# FM33FH0XX register map
File version: 1.0
CPU: SC000 r1p0, little endian, no MPU, no FPU, 3 interrupt priority bits
Registers are 32-bit, read-write, reset 0x0 unless marked. A register's access mark holds for its fields unless they carry their own. Offsets are from the block's base; [hi:lo] are bit positions; {n}, {i} and the like mark numbered series.

## RTC — RTC module information
Base 0x40011000
0x00 WER
  [0] WE — WE field description
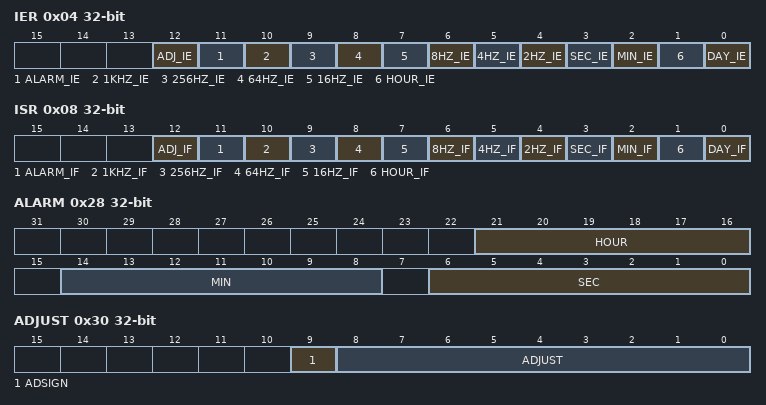
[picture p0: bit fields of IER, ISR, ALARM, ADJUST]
0x04 IER
  [12] ADJ_IE — ADJ_IE field description
  [11] ALARM_IE — ALARM_IE field description
  [10] 1KHZ_IE — 1KHZ_IE field description
  [9] 256HZ_IE — 256HZ_IE field description
  [8] 64HZ_IE — 64HZ_IE field description
  [7] 16HZ_IE — 16HZ_IE field description
  [6] 8HZ_IE — 8HZ_IE field description
  [5] 4HZ_IE — 4HZ_IE field description
  [4] 2HZ_IE — 2HZ_IE field description
  [3] SEC_IE — SEC_IE field description
  [2] MIN_IE — MIN_IE field description
  [1] HOUR_IE — HOUR_IE field description
  [0] DAY_IE — DAY_IE field description
0x08 ISR
  [12] ADJ_IF — ADJ_IF field description
  [11] ALARM_IF — ALARM_IF field description
  [10] 1KHZ_IF — 1KHZ_IF field description
  [9] 256HZ_IF — 256HZ_IF field description
  [8] 64HZ_IF — 64HZ_IF field description
  [7] 16HZ_IF — 16HZ_IF field description
  [6] 8HZ_IF — 8HZ_IF field description
  [5] 4HZ_IF — 4HZ_IF field description
  [4] 2HZ_IF — 2HZ_IF field description
  [3] SEC_IF — SEC_IF field description
  [2] MIN_IF — MIN_IF field description
  [1] HOUR_IF — HOUR_IF field description
  [0] DAY_IF — DAY_IF field description
0x0C BCDSEC
  [6:0] SEC — SEC field description
0x10 BCDMIN
  [6:0] MIN — MIN field description
0x14 BCDHOUR
  [5:0] HOUR — HOUR field description
0x18 BCDDAY
  [5:0] DAY — DAY field description
0x1C BCDWEEK
  [2:0] WEEK — WEEK field description
0x20 BCDMONTH
  [4:0] MONTH — MONTH field description
0x24 BCDYEAR
  [7:0] YEAR — YEAR field description
0x28 ALARM
  [21:16] HOUR — HOUR field description
  [14:8] MIN — MIN field description
  [6:0] SEC — SEC field description
0x2C TMSEL
  [3:0] TMSEL — TMSEL field description
0x30 ADJUST
  [9] ADSIGN — ADSIGN field description
  [8:0] ADJUST — ADJUST field description
0x3C MSECCNT
  [7:0] MSCNT — MSCNT field description
0x40 RTCA_CR
  [0] RTCA_EN — RTCA_EN field description

## SCU — SCU module information
Base 0x40000000
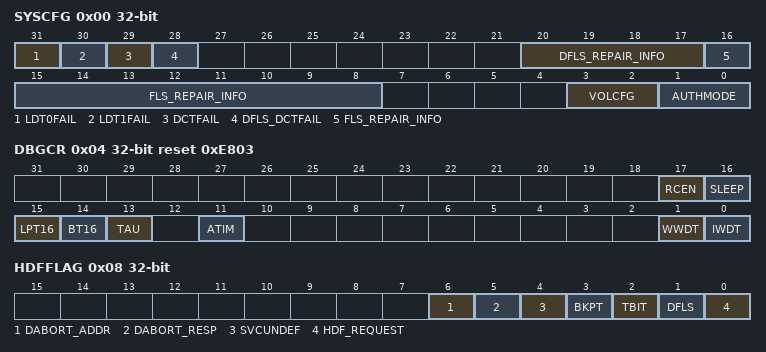
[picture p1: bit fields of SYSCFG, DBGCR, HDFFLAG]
0x00 SYSCFG
  [31] LDT0FAIL ro — LDT0FAIL field description
  [30] LDT1FAIL ro — LDT1FAIL field description
  [29] DCTFAIL ro — DCTFAIL field description
  [28] DFLS_DCTFAIL ro — DFLS_DCTFAIL field description
  [20:17] DFLS_REPAIR_INFO ro — DFLS_REPAIR_INFO field description
  [16:8] FLS_REPAIR_INFO ro — FLS_REPAIR_INFO field description
  [3:2] VOLCFG ro — VOLCFG field description
  [1:0] AUTHMODE ro — AUTHMODE field description
0x04 DBGCR reset 0xE803
  [17] RCEN — RCEN field description
  [16] SLEEP — SLEEP field description
  [15] LPT16 — LPT16 field description
  [14] BT16 — BT16 field description
  [13] TAU — TAU field description
  [11] ATIM — ATIM field description
  [1] WWDT — WWDT field description
  [0] IWDT — IWDT field description
0x08 HDFFLAG
  [6] DABORT_ADDR — DABORT_ADDR field description
  [5] DABORT_RESP — DABORT_RESP field description
  [4] SVCUNDEF — SVCUNDEF field description
  [3] BKPT — BKPT field description
  [2] TBIT — TBIT field description
  [1] DFLS — DFLS field description
  [0] HDF_REQUEST — HDF_REQUEST field description

## SENT0 — SENT0 module information
Base 0x40014800
Same registers: SENT1 0x40014C00
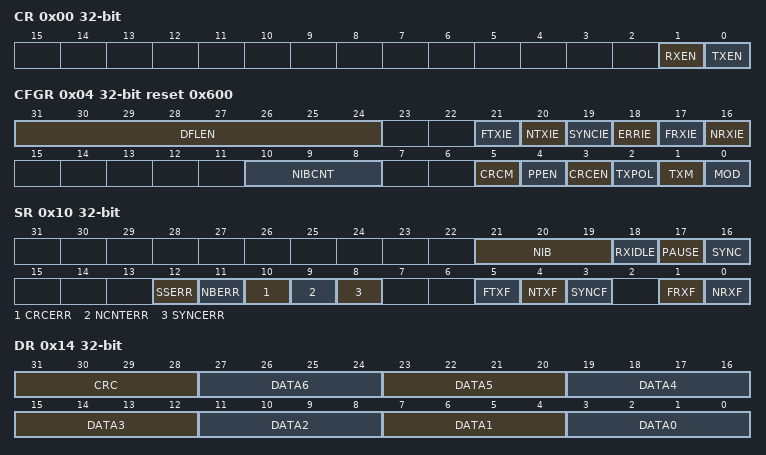
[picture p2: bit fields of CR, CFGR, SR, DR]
0x00 CR
  [1] RXEN — RXEN field description
  [0] TXEN — TXEN field description
0x04 CFGR reset 0x600
  [31:24] DFLEN — DFLEN field description
  [21] FTXIE — FTXIE field description
  [20] NTXIE — NTXIE field description
  [19] SYNCIE — SYNCIE field description
  [18] ERRIE — ERRIE field description
  [17] FRXIE — FRXIE field description
  [16] NRXIE — NRXIE field description
  [10:8] NIBCNT — NIBCNT field description
  [5] CRCM — CRCM field description
  [4] PPEN — PPEN field description
  [3] CRCEN — CRCEN field description
  [2] TXPOL — TXPOL field description
  [1] TXM — TXM field description
  [0] MOD — MOD field description
0x08 PSR reset 0x1
  [15:0] PSC — PSC field description
0x0C FTR reset 0x40E
  [11:0] LEN — LEN field description
0x10 SR
  [21:19] NIB ro — NIB field description
  [18] RXIDLE — RXIDLE field description
  [17] PAUSE — PAUSE field description
  [16] SYNC — SYNC field description
  [12] SSERR — SSERR field description
  [11] NBERR — NBERR field description
  [10] CRCERR — CRCERR field description
  [9] NCNTERR — NCNTERR field description
  [8] SYNCERR — SYNCERR field description
  [5] FTXF — FTXF field description
  [4] NTXF — NTXF field description
  [3] SYNCF — SYNCF field description
  [1] FRXF — FRXF field description
  [0] NRXF — NRXF field description
0x14 DR
  [31:28] CRC — CRC field description
  [4n+3:4n] DATA{n} (n=0..6) — DATA{n} field description
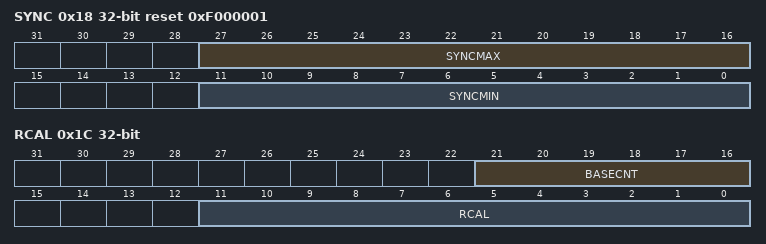
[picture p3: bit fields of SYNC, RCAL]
0x18 SYNC reset 0xF000001
  [27:16] SYNCMAX — SYNCMAX field description
  [11:0] SYNCMIN — SYNCMIN field description
0x1C RCAL
  [21:16] BASECNT ro — BASECNT field description
  [11:0] RCAL ro — RCAL field description
